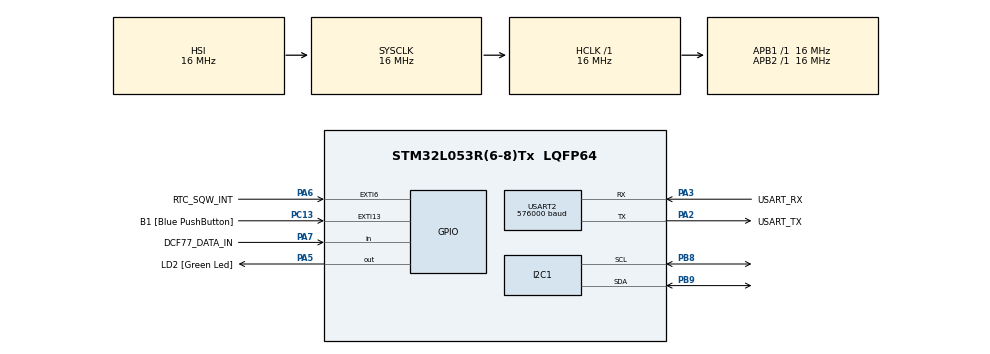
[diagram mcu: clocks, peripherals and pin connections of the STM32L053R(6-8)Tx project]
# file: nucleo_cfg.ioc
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I2C1.Timing=0x00303D5B
Mcu.Family=STM32L0
Mcu.Name=STM32L053R(6-8)Tx
Mcu.Package=LQFP64
NVIC.EXTI4_15_IRQn=true\:0\:0\:false\:false\:true
NVIC.I2C1_IRQn=true\:0\:0\:false\:false\:true
NVIC.USART2_IRQn=true\:0\:0\:false\:false\:true
PA13.GPIO_Label=TMS
PA13.Signal=SYS_SWDIO
PA14.GPIO_Label=TCK
PA14.Signal=SYS_SWCLK
PA2.GPIO_Label=USART_TX
PA2.Mode=Asynchronous
PA2.Signal=USART2_TX
PA3.GPIO_Label=USART_RX
PA3.Mode=Asynchronous
PA3.Signal=USART2_RX
PA5.GPIO_Label=LD2 [Green Led]
PA5.Signal=GPIO_Output
PA6.GPIO_Label=RTC_SQW_INT
PA6.GPIO_PuPd=GPIO_PULLUP
PA6.Signal=GPXTI6
PA7.GPIO_Label=DCF77_DATA_IN
PA7.GPIO_PuPd=GPIO_PULLUP
PA7.Signal=GPIO_Input
PB8.GPIO_FM8=__NULL
PB8.Mode=I2C
PB8.Signal=I2C1_SCL
PB9.GPIO_FM9=__NULL
PB9.Mode=I2C
PB9.Signal=I2C1_SDA
PC13.GPIO_Label=B1 [Blue PushButton]
PC13.GPIO_ModeDefaultEXTI=GPIO_MODE_EVT_RISING
PC13.Signal=GPXTI13
PC14-OSC32_IN.Signal=RCC_OSC32_IN
PC15-OSC32_OUT.Signal=RCC_OSC32_OUT
PH0-OSC_IN.Signal=RCC_OSC_IN
PH1-OSC_OUT.Signal=RCC_OSC_OUT
ProjectManager.HeapSize=0x200
ProjectManager.StackSize=0x400
ProjectManager.TargetToolchain=SW4STM32
RCC.AHBFreq_Value=16000000
RCC.APB1Freq_Value=16000000
RCC.APB1TimFreq_Value=16000000
RCC.APB2Freq_Value=16000000
RCC.APB2TimFreq_Value=16000000
RCC.HCLKFreq_Value=16000000
RCC.HSE_VALUE=8000000
RCC.HSI16_VALUE=16000000
RCC.HSI48_VALUE=48000000
RCC.HSI_VALUE=16000000
RCC.LSEState=RCC_LSE_ON
RCC.LSE_VALUE=32768
RCC.MSI_VALUE=2097000
RCC.PLLDIV=RCC_PLLDIV_3
RCC.SYSCLKFreq_VALUE=16000000
RCC.SYSCLKSource=RCC_SYSCLKSOURCE_HSI
RCC.VCOOutputFreq_Value=48000000
USART2.BaudRate=576000
USART2.Mode=UART_MODE_TX_RX
USART2.WordLength=UART_WORDLENGTH_8B
board=NUCLEO-L053R8

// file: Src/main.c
/**
  ******************************************************************************
  * File Name          : main.c
  * Description        : Main program body
  ******************************************************************************
  *
  * COPYRIGHT(c) 2016 STMicroelectronics
  *
  * Redistribution and use in source and binary forms, with or without modification,
  * are permitted provided that the following conditions are met:
  *   1. Redistributions of source code must retain the above copyright notice,
  *      this list of conditions and the following disclaimer.
  *   2. Redistributions in binary form must reproduce the above copyright notice,
  *      this list of conditions and the following disclaimer in the documentation
  *      and/or other materials provided with the distribution.
  *   3. Neither the name of STMicroelectronics nor the names of its contributors
  *      may be used to endorse or promote products derived from this software
  *      without specific prior written permission.
  *
  * THIS SOFTWARE IS PROVIDED BY THE COPYRIGHT HOLDERS AND CONTRIBUTORS "AS IS"
  * AND ANY EXPRESS OR IMPLIED WARRANTIES, INCLUDING, BUT NOT LIMITED TO, THE
  * IMPLIED WARRANTIES OF MERCHANTABILITY AND FITNESS FOR A PARTICULAR PURPOSE ARE
  * DISCLAIMED. IN NO EVENT SHALL THE COPYRIGHT HOLDER OR CONTRIBUTORS BE LIABLE
  * FOR ANY DIRECT, INDIRECT, INCIDENTAL, SPECIAL, EXEMPLARY, OR CONSEQUENTIAL
  * DAMAGES (INCLUDING, BUT NOT LIMITED TO, PROCUREMENT OF SUBSTITUTE GOODS OR
  * SERVICES; LOSS OF USE, DATA, OR PROFITS; OR BUSINESS INTERRUPTION) HOWEVER
  * CAUSED AND ON ANY THEORY OF LIABILITY, WHETHER IN CONTRACT, STRICT LIABILITY,
  * OR TORT (INCLUDING NEGLIGENCE OR OTHERWISE) ARISING IN ANY WAY OUT OF THE USE
  * OF THIS SOFTWARE, EVEN IF ADVISED OF THE POSSIBILITY OF SUCH DAMAGE.
  *
  ******************************************************************************
  */
#include "stm32l0xx_hal.h"

/* USER CODE BEGIN Includes */
#include "main_app.h"
/* USER CODE END Includes */

I2C_HandleTypeDef hi2c1;

UART_HandleTypeDef huart2;

/* USER CODE BEGIN PV */
/* Private variables ---------------------------------------------------------*/

/* USER CODE END PV */

void SystemClock_Config(void);
static void MX_GPIO_Init(void);
static void MX_I2C1_Init(void);
static void MX_USART2_UART_Init(void);

/* USER CODE BEGIN PFP */
/* Private function prototypes -----------------------------------------------*/

/* USER CODE END PFP */

int main(void)
{

  /* MCU Configuration----------------------------------------------------------*/

  /* Reset of all peripherals, Initializes the Flash interface and the Systick. */
  HAL_Init();

  /* Configure the system clock */
  SystemClock_Config();

  /* Initialize all configured peripherals */
  MX_GPIO_Init();
  MX_I2C1_Init();
  MX_USART2_UART_Init();

  /* USER CODE BEGIN 2 */
  HAL_DBGMCU_EnableDBGSleepMode();
  HAL_SuspendTick();	// we don't want systick to wake us up every 1ms

  main_app();
  /* USER CODE END 2 */

  /* Infinite loop */
  while (1)
  {

  /* USER CODE BEGIN 3 */
	  HAL_PWR_EnterSTOPMode(PWR_MAINREGULATOR_ON, PWR_STOPENTRY_WFI);
  }
  /* USER CODE END 3 */

}

/** System Clock Configuration
*/
void SystemClock_Config(void)
{

  RCC_OscInitTypeDef RCC_OscInitStruct;
  RCC_ClkInitTypeDef RCC_ClkInitStruct;
  RCC_PeriphCLKInitTypeDef PeriphClkInit;

  __HAL_RCC_PWR_CLK_ENABLE();

  __HAL_PWR_VOLTAGESCALING_CONFIG(PWR_REGULATOR_VOLTAGE_SCALE1);

  RCC_OscInitStruct.OscillatorType = RCC_OSCILLATORTYPE_HSI;
  RCC_OscInitStruct.HSIState = RCC_HSI_ON;
  RCC_OscInitStruct.HSICalibrationValue = 16;
  RCC_OscInitStruct.PLL.PLLState = RCC_PLL_NONE;
  HAL_RCC_OscConfig(&RCC_OscInitStruct);

  RCC_ClkInitStruct.ClockType = RCC_CLOCKTYPE_HCLK|RCC_CLOCKTYPE_SYSCLK
                              |RCC_CLOCKTYPE_PCLK1|RCC_CLOCKTYPE_PCLK2;
  RCC_ClkInitStruct.SYSCLKSource = RCC_SYSCLKSOURCE_HSI;
  RCC_ClkInitStruct.AHBCLKDivider = RCC_SYSCLK_DIV1;
  RCC_ClkInitStruct.APB1CLKDivider = RCC_HCLK_DIV1;
  RCC_ClkInitStruct.APB2CLKDivider = RCC_HCLK_DIV1;
  HAL_RCC_ClockConfig(&RCC_ClkInitStruct, FLASH_LATENCY_0);

  PeriphClkInit.PeriphClockSelection = RCC_PERIPHCLK_USART2|RCC_PERIPHCLK_I2C1;
  PeriphClkInit.Usart2ClockSelection = RCC_USART2CLKSOURCE_PCLK1;
  PeriphClkInit.I2c1ClockSelection = RCC_I2C1CLKSOURCE_PCLK1;
  HAL_RCCEx_PeriphCLKConfig(&PeriphClkInit);

  HAL_SYSTICK_Config(HAL_RCC_GetHCLKFreq()/1000);

  HAL_SYSTICK_CLKSourceConfig(SYSTICK_CLKSOURCE_HCLK);

  /* SysTick_IRQn interrupt configuration */
  HAL_NVIC_SetPriority(SysTick_IRQn, 0, 0);
}

/* I2C1 init function */
void MX_I2C1_Init(void)
{

  hi2c1.Instance = I2C1;
  hi2c1.Init.Timing = 0x00303D5B;
  hi2c1.Init.OwnAddress1 = 0;
  hi2c1.Init.AddressingMode = I2C_ADDRESSINGMODE_7BIT;
  hi2c1.Init.DualAddressMode = I2C_DUALADDRESS_DISABLE;
  hi2c1.Init.OwnAddress2 = 0;
  hi2c1.Init.OwnAddress2Masks = I2C_OA2_NOMASK;
  hi2c1.Init.GeneralCallMode = I2C_GENERALCALL_DISABLE;
  hi2c1.Init.NoStretchMode = I2C_NOSTRETCH_DISABLE;
  HAL_I2C_Init(&hi2c1);

    /**Configure Analogue filter
    */
  HAL_I2CEx_ConfigAnalogFilter(&hi2c1, I2C_ANALOGFILTER_ENABLE);

}

/* USART2 init function */
void MX_USART2_UART_Init(void)
{

  huart2.Instance = USART2;
  huart2.Init.BaudRate = 576000;
  huart2.Init.WordLength = UART_WORDLENGTH_8B;
  huart2.Init.StopBits = UART_STOPBITS_1;
  huart2.Init.Parity = UART_PARITY_NONE;
  huart2.Init.Mode = UART_MODE_TX_RX;
  huart2.Init.HwFlowCtl = UART_HWCONTROL_NONE;
  huart2.Init.OverSampling = UART_OVERSAMPLING_16;
  huart2.Init.OneBitSampling = UART_ONE_BIT_SAMPLE_DISABLE;
  huart2.AdvancedInit.AdvFeatureInit = UART_ADVFEATURE_NO_INIT;
  HAL_UART_Init(&huart2);

}

/** Configure pins as
        * Analog
        * Input
        * Output
        * EVENT_OUT
        * EXTI
*/
void MX_GPIO_Init(void)
{

  GPIO_InitTypeDef GPIO_InitStruct;

  /* GPIO Ports Clock Enable */
  __HAL_RCC_GPIOC_CLK_ENABLE();
  __HAL_RCC_GPIOH_CLK_ENABLE();
  __HAL_RCC_GPIOA_CLK_ENABLE();
  __HAL_RCC_GPIOB_CLK_ENABLE();

  /*Configure GPIO pin : B1_Pin */
  GPIO_InitStruct.Pin = B1_Pin;
  GPIO_InitStruct.Mode = GPIO_MODE_EVT_RISING;
  GPIO_InitStruct.Pull = GPIO_NOPULL;
  HAL_GPIO_Init(B1_GPIO_Port, &GPIO_InitStruct);

  /*Configure GPIO pin : LD2_Pin */
  GPIO_InitStruct.Pin = LD2_Pin;
  GPIO_InitStruct.Mode = GPIO_MODE_OUTPUT_PP;
  GPIO_InitStruct.Pull = GPIO_NOPULL;
  GPIO_InitStruct.Speed = GPIO_SPEED_FREQ_LOW;
  HAL_GPIO_Init(LD2_GPIO_Port, &GPIO_InitStruct);

  /*Configure GPIO pin : RTC_SQW_INT_Pin */
  GPIO_InitStruct.Pin = RTC_SQW_INT_Pin;
  GPIO_InitStruct.Mode = GPIO_MODE_IT_RISING;
  GPIO_InitStruct.Pull = GPIO_PULLUP;
  HAL_GPIO_Init(RTC_SQW_INT_GPIO_Port, &GPIO_InitStruct);

  /*Configure GPIO pin : DCF77_DATA_IN_Pin */
  GPIO_InitStruct.Pin = DCF77_DATA_IN_Pin;
  GPIO_InitStruct.Mode = GPIO_MODE_INPUT;
  GPIO_InitStruct.Pull = GPIO_PULLUP;
  HAL_GPIO_Init(DCF77_DATA_IN_GPIO_Port, &GPIO_InitStruct);

  /*Configure GPIO pin Output Level */
  HAL_GPIO_WritePin(LD2_GPIO_Port, LD2_Pin, GPIO_PIN_RESET);

  /* EXTI interrupt init*/
  HAL_NVIC_SetPriority(EXTI4_15_IRQn, 0, 0);
  HAL_NVIC_EnableIRQ(EXTI4_15_IRQn);

}

#ifdef USE_FULL_ASSERT

/**
   * @brief Reports the name of the source file and the source line number
   * where the assert_param error has occurred.
   * @param file: pointer to the source file name
   * @param line: assert_param error line source number
   * @retval None
   */
void assert_failed(uint8_t* file, uint32_t line)
{
  /* USER CODE BEGIN 6 */
  /* User can add his own implementation to report the file name and line number,
    ex: printf("Wrong parameters value: file %s on line %d\r\n", file, line) */
	while(1) {};
  /* USER CODE END 6 */

}

#endif

/************************ (C) COPYRIGHT STMicroelectronics *****END OF FILE****/
